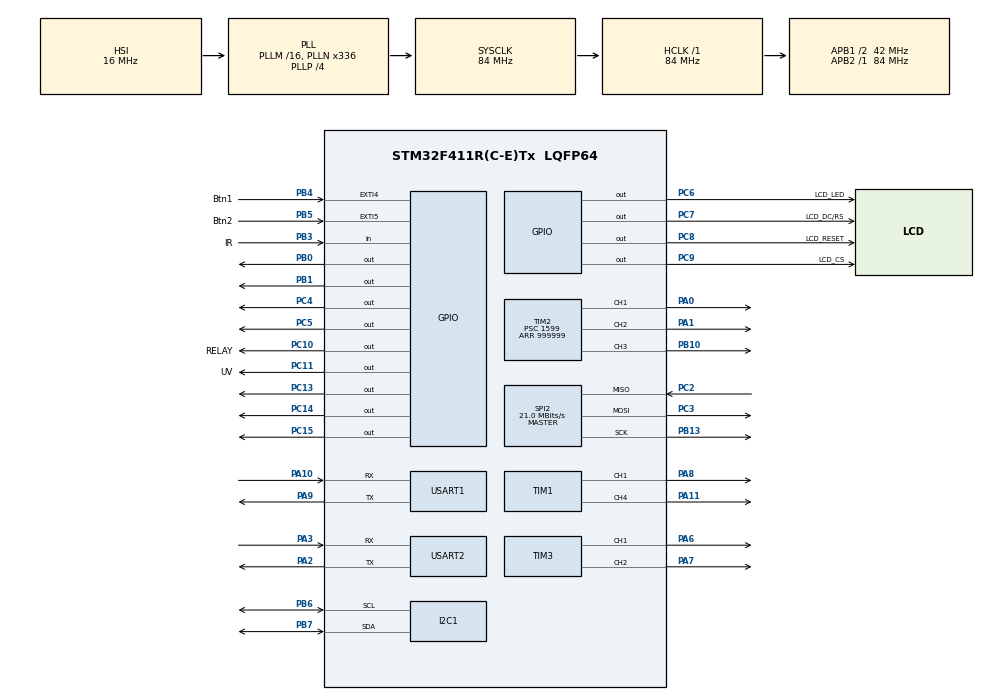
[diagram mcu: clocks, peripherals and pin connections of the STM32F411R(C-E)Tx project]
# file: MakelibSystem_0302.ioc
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FREERTOS.Tasks01=SensorTask,1,128,StartGetSensor,Default,NULL,Dynamic,NULL,NULL;ControlTask,0,128,StartControl,Default,NULL,Dynamic,NULL,NULL;DisplayTask,-1,128,StartDisplayTask,Default,NULL,Dynamic,NULL,NULL;ServerTask,1,128,StartServerTask,Default,NULL,Dynamic,NULL,NULL
Mcu.Family=STM32F4
Mcu.Name=STM32F411R(C-E)Tx
Mcu.Package=LQFP64
NVIC.PriorityGroup=NVIC_PRIORITYGROUP_4
NVIC.TIM4_IRQn=true\:0\:0\:false\:false\:true\:false\:false\:true
NVIC.TimeBase=TIM4_IRQn
NVIC.TimeBaseIP=TIM4
PA0-WKUP.Signal=S_TIM2_CH1_ETR
PA1.Signal=S_TIM2_CH2
PA10.Mode=Asynchronous
PA10.Signal=USART1_RX
PA11.Signal=S_TIM1_CH4
PA2.Mode=Asynchronous
PA2.Signal=USART2_TX
PA3.Mode=Asynchronous
PA3.Signal=USART2_RX
PA6.Signal=S_TIM3_CH1
PA7.Signal=S_TIM3_CH2
PA8.Signal=S_TIM1_CH1
PA9.Mode=Asynchronous
PA9.Signal=USART1_TX
PB0.Signal=GPIO_Output
PB1.Signal=GPIO_Output
PB10.Signal=S_TIM2_CH3
PB13.Mode=Full_Duplex_Master
PB13.Signal=SPI2_SCK
PB3.GPIO_Label=IR
PB3.Signal=GPIO_Input
PB4.GPIO_Label=Btn1
PB4.Signal=GPXTI4
PB5.GPIO_Label=Btn2
PB5.Signal=GPXTI5
PB6.Mode=I2C
PB6.Signal=I2C1_SCL
PB7.Mode=I2C
PB7.Signal=I2C1_SDA
PC10.GPIO_Label=RELAY
PC10.Signal=GPIO_Output
PC11.GPIO_Label=UV
PC11.Signal=GPIO_Output
PC13-ANTI_TAMP.Signal=GPIO_Output
PC14-OSC32_IN.Signal=GPIO_Output
PC15-OSC32_OUT.Signal=GPIO_Output
PC2.Mode=Full_Duplex_Master
PC2.Signal=SPI2_MISO
PC3.Mode=Full_Duplex_Master
PC3.Signal=SPI2_MOSI
PC4.Signal=GPIO_Output
PC5.Signal=GPIO_Output
PC6.GPIO_Label=LCD_LED
PC6.PinState=GPIO_PIN_SET
PC6.Signal=GPIO_Output
PC7.GPIO_Label=LCD_DC/RS
PC7.PinState=GPIO_PIN_SET
PC7.Signal=GPIO_Output
PC8.GPIO_Label=LCD_RESET
PC8.PinState=GPIO_PIN_SET
PC8.Signal=GPIO_Output
PC9.GPIO_Label=LCD_CS
PC9.PinState=GPIO_PIN_SET
PC9.Signal=GPIO_Output
PH0\ -\ OSC_IN.Mode=HSE-External-Oscillator
PH0\ -\ OSC_IN.Signal=RCC_OSC_IN
PH1\ -\ OSC_OUT.Mode=HSE-External-Oscillator
PH1\ -\ OSC_OUT.Signal=RCC_OSC_OUT
ProjectManager.HeapSize=0x200
ProjectManager.StackSize=0x400
ProjectManager.TargetToolchain=STM32CubeIDE
RCC.48MHZClocksFreq_Value=84000000
RCC.AHBFreq_Value=84000000
RCC.APB1CLKDivider=RCC_HCLK_DIV2
RCC.APB1Freq_Value=42000000
RCC.APB1TimFreq_Value=84000000
RCC.APB2Freq_Value=84000000
RCC.APB2TimFreq_Value=84000000
RCC.CortexFreq_Value=84000000
RCC.HCLKFreq_Value=84000000
RCC.HSE_VALUE=25000000
RCC.HSI_VALUE=16000000
RCC.LSE_VALUE=32768
RCC.PLLN=336
RCC.PLLP=RCC_PLLP_DIV4
RCC.SYSCLKFreq_VALUE=84000000
RCC.SYSCLKSource=RCC_SYSCLKSOURCE_PLLCLK
RCC.VCOOutputFreq_Value=336000000
SH.S_TIM1_CH1.0=TIM1_CH1,PWM Generation1 CH1
SH.S_TIM1_CH4.0=TIM1_CH4,PWM Generation4 CH4
SH.S_TIM2_CH1_ETR.0=TIM2_CH1,PWM Generation1 CH1
SH.S_TIM2_CH2.0=TIM2_CH2,PWM Generation2 CH2
SH.S_TIM2_CH3.0=TIM2_CH3,PWM Generation3 CH3
SH.S_TIM3_CH1.0=TIM3_CH1,PWM Generation1 CH1
SH.S_TIM3_CH2.0=TIM3_CH2,PWM Generation2 CH2
SPI2.CalculateBaudRate=21.0 MBits/s
SPI2.Direction=SPI_DIRECTION_2LINES
SPI2.Mode=SPI_MODE_MASTER
SPI2.VirtualType=VM_MASTER
TIM1.Channel-PWM\ Generation1\ CH1=TIM_CHANNEL_1
TIM1.Channel-PWM\ Generation4\ CH4=TIM_CHANNEL_4
TIM2.Channel-PWM\ Generation1\ CH1=TIM_CHANNEL_1
TIM2.Channel-PWM\ Generation2\ CH2=TIM_CHANNEL_2
TIM2.Channel-PWM\ Generation3\ CH3=TIM_CHANNEL_3
TIM2.Period=999999
TIM2.Prescaler=1599
TIM3.Channel-PWM\ Generation1\ CH1=TIM_CHANNEL_1
TIM3.Channel-PWM\ Generation2\ CH2=TIM_CHANNEL_2
USART1.VirtualMode=VM_ASYNC
USART2.VirtualMode=VM_ASYNC
VP_FREERTOS_VS_CMSIS_V1.Mode=CMSIS_V1
VP_SYS_VS_tim4.Mode=TIM4
VP_TIM2_VS_ClockSourceINT.Mode=Internal
board=custom

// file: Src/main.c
/* USER CODE BEGIN Header */
/**
  ******************************************************************************
  * @file           : main.c
  * @brief          : Main program body
  ******************************************************************************
  * @attention
  *
  * <h2><center>&copy; Copyright (c) 2020 STMicroelectronics.
  * All rights reserved.</center></h2>
  *
  * This software component is licensed by ST under Ultimate Liberty license
  * SLA0044, the "License"; You may not use this file except in compliance with
  * the License. You may obtain a copy of the License at:
  *                             www.st.com/SLA0044
  *
  ******************************************************************************
  */
/* USER CODE END Header */

#include "main.h"
#include "cmsis_os.h"

I2C_HandleTypeDef hi2c1;

SPI_HandleTypeDef hspi2;

TIM_HandleTypeDef htim1;
TIM_HandleTypeDef htim2;
TIM_HandleTypeDef htim3;

UART_HandleTypeDef huart1;
UART_HandleTypeDef huart2;

osThreadId SensorTaskHandle;
osThreadId ControlTaskHandle;
osThreadId DisplayTaskHandle;
osThreadId ServerTaskHandle;
/* USER CODE BEGIN PV */
// Đây sẽ là phần khai báo biến toàn cục để sử dụng cho hệ thống, các biến này sẽ dùng để cập nhật trạng thái của cơ cấu chấp hành và thông số cảm biến

/* USER CODE END PV */

void SystemClock_Config(void);
static void MX_GPIO_Init(void);
static void MX_I2C1_Init(void);
static void MX_SPI2_Init(void);
static void MX_TIM1_Init(void);
static void MX_TIM2_Init(void);
static void MX_TIM3_Init(void);
static void MX_USART1_UART_Init(void);
static void MX_USART2_UART_Init(void);
void StartGetSensor(void const * argument);
void StartControl(void const * argument);
void StartDisplayTask(void const * argument);
void StartServerTask(void const * argument);

int main(void)
{

  /* MCU Configuration--------------------------------------------------------*/

  /* Reset of all peripherals, Initializes the Flash interface and the Systick. */
  HAL_Init();

  /* Configure the system clock */
  SystemClock_Config();

  /* Initialize all configured peripherals */
  MX_GPIO_Init();
  MX_I2C1_Init();
  MX_SPI2_Init();
  MX_TIM1_Init();
  MX_TIM2_Init();
  MX_TIM3_Init();
  MX_USART1_UART_Init();
  MX_USART2_UART_Init();
  /* USER CODE BEGIN 2 */
  // Khởi tạo các kết nối với ngoại vi ở đây

  /* USER CODE END 2 */

  /* Create the thread(s) */
  /* definition and creation of SensorTask */
  osThreadDef(SensorTask, StartGetSensor, osPriorityAboveNormal, 0, 128);
  SensorTaskHandle = osThreadCreate(osThread(SensorTask), NULL);

  /* definition and creation of ControlTask */
  osThreadDef(ControlTask, StartControl, osPriorityNormal, 0, 128);
  ControlTaskHandle = osThreadCreate(osThread(ControlTask), NULL);

  /* definition and creation of DisplayTask */
  osThreadDef(DisplayTask, StartDisplayTask, osPriorityBelowNormal, 0, 128);
  DisplayTaskHandle = osThreadCreate(osThread(DisplayTask), NULL);

  /* definition and creation of ServerTask */
  osThreadDef(ServerTask, StartServerTask, osPriorityAboveNormal, 0, 128);
  ServerTaskHandle = osThreadCreate(osThread(ServerTask), NULL);

  /* Start scheduler */
  osKernelStart();

  /* We should never get here as control is now taken by the scheduler */

  /* Infinite loop */
  while (1)
  {

  }
}

void SystemClock_Config(void)
{
  RCC_OscInitTypeDef RCC_OscInitStruct = {0};
  RCC_ClkInitTypeDef RCC_ClkInitStruct = {0};

  /** Configure the main internal regulator output voltage
  */
  __HAL_RCC_PWR_CLK_ENABLE();
  __HAL_PWR_VOLTAGESCALING_CONFIG(PWR_REGULATOR_VOLTAGE_SCALE1);
  /** Initializes the CPU, AHB and APB busses clocks
  */
  RCC_OscInitStruct.OscillatorType = RCC_OSCILLATORTYPE_HSI;
  RCC_OscInitStruct.HSIState = RCC_HSI_ON;
  RCC_OscInitStruct.HSICalibrationValue = RCC_HSICALIBRATION_DEFAULT;
  RCC_OscInitStruct.PLL.PLLState = RCC_PLL_ON;
  RCC_OscInitStruct.PLL.PLLSource = RCC_PLLSOURCE_HSI;
  RCC_OscInitStruct.PLL.PLLM = 16;
  RCC_OscInitStruct.PLL.PLLN = 336;
  RCC_OscInitStruct.PLL.PLLP = RCC_PLLP_DIV4;
  RCC_OscInitStruct.PLL.PLLQ = 4;
  if (HAL_RCC_OscConfig(&RCC_OscInitStruct) != HAL_OK)
  {
    Error_Handler();
  }
  /** Initializes the CPU, AHB and APB busses clocks
  */
  RCC_ClkInitStruct.ClockType = RCC_CLOCKTYPE_HCLK|RCC_CLOCKTYPE_SYSCLK
                              |RCC_CLOCKTYPE_PCLK1|RCC_CLOCKTYPE_PCLK2;
  RCC_ClkInitStruct.SYSCLKSource = RCC_SYSCLKSOURCE_PLLCLK;
  RCC_ClkInitStruct.AHBCLKDivider = RCC_SYSCLK_DIV1;
  RCC_ClkInitStruct.APB1CLKDivider = RCC_HCLK_DIV2;
  RCC_ClkInitStruct.APB2CLKDivider = RCC_HCLK_DIV1;

  if (HAL_RCC_ClockConfig(&RCC_ClkInitStruct, FLASH_LATENCY_2) != HAL_OK)
  {
    Error_Handler();
  }
}

static void MX_I2C1_Init(void)
{

  hi2c1.Instance = I2C1;
  hi2c1.Init.ClockSpeed = 100000;
  hi2c1.Init.DutyCycle = I2C_DUTYCYCLE_2;
  hi2c1.Init.OwnAddress1 = 0;
  hi2c1.Init.AddressingMode = I2C_ADDRESSINGMODE_7BIT;
  hi2c1.Init.DualAddressMode = I2C_DUALADDRESS_DISABLE;
  hi2c1.Init.OwnAddress2 = 0;
  hi2c1.Init.GeneralCallMode = I2C_GENERALCALL_DISABLE;
  hi2c1.Init.NoStretchMode = I2C_NOSTRETCH_DISABLE;
  if (HAL_I2C_Init(&hi2c1) != HAL_OK)
  {
    Error_Handler();
  }

}

static void MX_SPI2_Init(void)
{

  /* SPI2 parameter configuration*/
  hspi2.Instance = SPI2;
  hspi2.Init.Mode = SPI_MODE_MASTER;
  hspi2.Init.Direction = SPI_DIRECTION_2LINES;
  hspi2.Init.DataSize = SPI_DATASIZE_8BIT;
  hspi2.Init.CLKPolarity = SPI_POLARITY_LOW;
  hspi2.Init.CLKPhase = SPI_PHASE_1EDGE;
  hspi2.Init.NSS = SPI_NSS_SOFT;
  hspi2.Init.BaudRatePrescaler = SPI_BAUDRATEPRESCALER_2;
  hspi2.Init.FirstBit = SPI_FIRSTBIT_MSB;
  hspi2.Init.TIMode = SPI_TIMODE_DISABLE;
  hspi2.Init.CRCCalculation = SPI_CRCCALCULATION_DISABLE;
  hspi2.Init.CRCPolynomial = 10;
  if (HAL_SPI_Init(&hspi2) != HAL_OK)
  {
    Error_Handler();
  }

}

static void MX_TIM1_Init(void)
{

  TIM_MasterConfigTypeDef sMasterConfig = {0};
  TIM_OC_InitTypeDef sConfigOC = {0};
  TIM_BreakDeadTimeConfigTypeDef sBreakDeadTimeConfig = {0};

  htim1.Instance = TIM1;
  htim1.Init.Prescaler = 0;
  htim1.Init.CounterMode = TIM_COUNTERMODE_UP;
  htim1.Init.Period = 0;
  htim1.Init.ClockDivision = TIM_CLOCKDIVISION_DIV1;
  htim1.Init.RepetitionCounter = 0;
  htim1.Init.AutoReloadPreload = TIM_AUTORELOAD_PRELOAD_DISABLE;
  if (HAL_TIM_PWM_Init(&htim1) != HAL_OK)
  {
    Error_Handler();
  }
  sMasterConfig.MasterOutputTrigger = TIM_TRGO_RESET;
  sMasterConfig.MasterSlaveMode = TIM_MASTERSLAVEMODE_DISABLE;
  if (HAL_TIMEx_MasterConfigSynchronization(&htim1, &sMasterConfig) != HAL_OK)
  {
    Error_Handler();
  }
  sConfigOC.OCMode = TIM_OCMODE_PWM1;
  sConfigOC.Pulse = 0;
  sConfigOC.OCPolarity = TIM_OCPOLARITY_HIGH;
  sConfigOC.OCNPolarity = TIM_OCNPOLARITY_HIGH;
  sConfigOC.OCFastMode = TIM_OCFAST_DISABLE;
  sConfigOC.OCIdleState = TIM_OCIDLESTATE_RESET;
  sConfigOC.OCNIdleState = TIM_OCNIDLESTATE_RESET;
  if (HAL_TIM_PWM_ConfigChannel(&htim1, &sConfigOC, TIM_CHANNEL_1) != HAL_OK)
  {
    Error_Handler();
  }
  if (HAL_TIM_PWM_ConfigChannel(&htim1, &sConfigOC, TIM_CHANNEL_4) != HAL_OK)
  {
    Error_Handler();
  }
  sBreakDeadTimeConfig.OffStateRunMode = TIM_OSSR_DISABLE;
  sBreakDeadTimeConfig.OffStateIDLEMode = TIM_OSSI_DISABLE;
  sBreakDeadTimeConfig.LockLevel = TIM_LOCKLEVEL_OFF;
  sBreakDeadTimeConfig.DeadTime = 0;
  sBreakDeadTimeConfig.BreakState = TIM_BREAK_DISABLE;
  sBreakDeadTimeConfig.BreakPolarity = TIM_BREAKPOLARITY_HIGH;
  sBreakDeadTimeConfig.AutomaticOutput = TIM_AUTOMATICOUTPUT_DISABLE;
  if (HAL_TIMEx_ConfigBreakDeadTime(&htim1, &sBreakDeadTimeConfig) != HAL_OK)
  {
    Error_Handler();
  }
  HAL_TIM_MspPostInit(&htim1);

}

static void MX_TIM2_Init(void)
{

  TIM_ClockConfigTypeDef sClockSourceConfig = {0};
  TIM_MasterConfigTypeDef sMasterConfig = {0};
  TIM_OC_InitTypeDef sConfigOC = {0};

  htim2.Instance = TIM2;
  htim2.Init.Prescaler = 1599;
  htim2.Init.CounterMode = TIM_COUNTERMODE_UP;
  htim2.Init.Period = 999999;
  htim2.Init.ClockDivision = TIM_CLOCKDIVISION_DIV1;
  htim2.Init.AutoReloadPreload = TIM_AUTORELOAD_PRELOAD_DISABLE;
  if (HAL_TIM_Base_Init(&htim2) != HAL_OK)
  {
    Error_Handler();
  }
  sClockSourceConfig.ClockSource = TIM_CLOCKSOURCE_INTERNAL;
  if (HAL_TIM_ConfigClockSource(&htim2, &sClockSourceConfig) != HAL_OK)
  {
    Error_Handler();
  }
  if (HAL_TIM_PWM_Init(&htim2) != HAL_OK)
  {
    Error_Handler();
  }
  sMasterConfig.MasterOutputTrigger = TIM_TRGO_RESET;
  sMasterConfig.MasterSlaveMode = TIM_MASTERSLAVEMODE_DISABLE;
  if (HAL_TIMEx_MasterConfigSynchronization(&htim2, &sMasterConfig) != HAL_OK)
  {
    Error_Handler();
  }
  sConfigOC.OCMode = TIM_OCMODE_PWM1;
  sConfigOC.Pulse = 0;
  sConfigOC.OCPolarity = TIM_OCPOLARITY_HIGH;
  sConfigOC.OCFastMode = TIM_OCFAST_DISABLE;
  if (HAL_TIM_PWM_ConfigChannel(&htim2, &sConfigOC, TIM_CHANNEL_1) != HAL_OK)
  {
    Error_Handler();
  }
  if (HAL_TIM_PWM_ConfigChannel(&htim2, &sConfigOC, TIM_CHANNEL_2) != HAL_OK)
  {
    Error_Handler();
  }
  if (HAL_TIM_PWM_ConfigChannel(&htim2, &sConfigOC, TIM_CHANNEL_3) != HAL_OK)
  {
    Error_Handler();
  }
  HAL_TIM_MspPostInit(&htim2);

}

static void MX_TIM3_Init(void)
{

  TIM_MasterConfigTypeDef sMasterConfig = {0};
  TIM_OC_InitTypeDef sConfigOC = {0};

  htim3.Instance = TIM3;
  htim3.Init.Prescaler = 0;
  htim3.Init.CounterMode = TIM_COUNTERMODE_UP;
  htim3.Init.Period = 0;
  htim3.Init.ClockDivision = TIM_CLOCKDIVISION_DIV1;
  htim3.Init.AutoReloadPreload = TIM_AUTORELOAD_PRELOAD_DISABLE;
  if (HAL_TIM_PWM_Init(&htim3) != HAL_OK)
  {
    Error_Handler();
  }
  sMasterConfig.MasterOutputTrigger = TIM_TRGO_RESET;
  sMasterConfig.MasterSlaveMode = TIM_MASTERSLAVEMODE_DISABLE;
  if (HAL_TIMEx_MasterConfigSynchronization(&htim3, &sMasterConfig) != HAL_OK)
  {
    Error_Handler();
  }
  sConfigOC.OCMode = TIM_OCMODE_PWM1;
  sConfigOC.Pulse = 0;
  sConfigOC.OCPolarity = TIM_OCPOLARITY_HIGH;
  sConfigOC.OCFastMode = TIM_OCFAST_DISABLE;
  if (HAL_TIM_PWM_ConfigChannel(&htim3, &sConfigOC, TIM_CHANNEL_1) != HAL_OK)
  {
    Error_Handler();
  }
  if (HAL_TIM_PWM_ConfigChannel(&htim3, &sConfigOC, TIM_CHANNEL_2) != HAL_OK)
  {
    Error_Handler();
  }
  HAL_TIM_MspPostInit(&htim3);

}

static void MX_USART1_UART_Init(void)
{

  huart1.Instance = USART1;
  huart1.Init.BaudRate = 115200;
  huart1.Init.WordLength = UART_WORDLENGTH_8B;
  huart1.Init.StopBits = UART_STOPBITS_1;
  huart1.Init.Parity = UART_PARITY_NONE;
  huart1.Init.Mode = UART_MODE_TX_RX;
  huart1.Init.HwFlowCtl = UART_HWCONTROL_NONE;
  huart1.Init.OverSampling = UART_OVERSAMPLING_16;
  if (HAL_UART_Init(&huart1) != HAL_OK)
  {
    Error_Handler();
  }

}

static void MX_USART2_UART_Init(void)
{

  huart2.Instance = USART2;
  huart2.Init.BaudRate = 115200;
  huart2.Init.WordLength = UART_WORDLENGTH_8B;
  huart2.Init.StopBits = UART_STOPBITS_1;
  huart2.Init.Parity = UART_PARITY_NONE;
  huart2.Init.Mode = UART_MODE_TX_RX;
  huart2.Init.HwFlowCtl = UART_HWCONTROL_NONE;
  huart2.Init.OverSampling = UART_OVERSAMPLING_16;
  if (HAL_UART_Init(&huart2) != HAL_OK)
  {
    Error_Handler();
  }

}

static void MX_GPIO_Init(void)
{
  GPIO_InitTypeDef GPIO_InitStruct = {0};

  /* GPIO Ports Clock Enable */
  __HAL_RCC_GPIOC_CLK_ENABLE();
  __HAL_RCC_GPIOH_CLK_ENABLE();
  __HAL_RCC_GPIOA_CLK_ENABLE();
  __HAL_RCC_GPIOB_CLK_ENABLE();

  /*Configure GPIO pin Output Level */
  HAL_GPIO_WritePin(GPIOC, GPIO_PIN_13|GPIO_PIN_14|GPIO_PIN_15|GPIO_PIN_4
                          |GPIO_PIN_5|RELAY_Pin|UV_Pin, GPIO_PIN_RESET);

  /*Configure GPIO pin Output Level */
  HAL_GPIO_WritePin(GPIOB, GPIO_PIN_0|GPIO_PIN_1, GPIO_PIN_RESET);

  /*Configure GPIO pin Output Level */
  HAL_GPIO_WritePin(GPIOC, LCD_LED_Pin|LCD_DC_RS_Pin|LCD_RESET_Pin|LCD_CS_Pin, GPIO_PIN_SET);

  /*Configure GPIO pins : PC13 PC14 PC15 PC4
                           PC5 LCD_LED_Pin LCD_DC_RS_Pin LCD_RESET_Pin
                           LCD_CS_Pin RELAY_Pin UV_Pin */
  GPIO_InitStruct.Pin = GPIO_PIN_13|GPIO_PIN_14|GPIO_PIN_15|GPIO_PIN_4
                          |GPIO_PIN_5|LCD_LED_Pin|LCD_DC_RS_Pin|LCD_RESET_Pin
                          |LCD_CS_Pin|RELAY_Pin|UV_Pin;
  GPIO_InitStruct.Mode = GPIO_MODE_OUTPUT_PP;
  GPIO_InitStruct.Pull = GPIO_NOPULL;
  GPIO_InitStruct.Speed = GPIO_SPEED_FREQ_LOW;
  HAL_GPIO_Init(GPIOC, &GPIO_InitStruct);

  /*Configure GPIO pins : PB0 PB1 */
  GPIO_InitStruct.Pin = GPIO_PIN_0|GPIO_PIN_1;
  GPIO_InitStruct.Mode = GPIO_MODE_OUTPUT_PP;
  GPIO_InitStruct.Pull = GPIO_NOPULL;
  GPIO_InitStruct.Speed = GPIO_SPEED_FREQ_LOW;
  HAL_GPIO_Init(GPIOB, &GPIO_InitStruct);

  /*Configure GPIO pin : IR_Pin */
  GPIO_InitStruct.Pin = IR_Pin;
  GPIO_InitStruct.Mode = GPIO_MODE_INPUT;
  GPIO_InitStruct.Pull = GPIO_NOPULL;
  HAL_GPIO_Init(IR_GPIO_Port, &GPIO_InitStruct);

  /*Configure GPIO pins : Btn1_Pin Btn2_Pin */
  GPIO_InitStruct.Pin = Btn1_Pin|Btn2_Pin;
  GPIO_InitStruct.Mode = GPIO_MODE_IT_RISING;
  GPIO_InitStruct.Pull = GPIO_NOPULL;
  HAL_GPIO_Init(GPIOB, &GPIO_InitStruct);

}

// Đọc các giá trị từ cảm biến và lưu ở đây
void StartGetSensor(void const * argument)
{
    // Lấy giá trị từ cảm biến và lưu vào biến toàn cục được define ở trên

  /* USER CODE BEGIN 5 */
  /* Infinite loop */
  for(;;)
  {
	// Cứ 2s sẽ tiến hành lấy giá trị cảm biến 1 lần
    osDelay(2000);
  }
  /* USER CODE END 5 */
}

// Xét chế độ điều khiển ở đây
void StartControl(void const * argument)
{

  /* USER CODE BEGIN StartControl */
  /* Infinite loop */
	// Xét tín hiệu điều khiển từ nút bấm và IR
	// Ở đây sẽ xét cho chế độ điều khiển hay tự động, nếu chế độ tự động thì sẽ xét các biến lấy từ cảm biến ở đây để điều khiển

  for(;;)
  {
	// 1s sẽ xét chế độ 1 lần
    osDelay(1000);
  }
  /* USER CODE END StartControl */
}

// Task điều khiển tín hiệu màn hình
void StartDisplayTask(void const * argument)
{
  /* USER CODE BEGIN StartDisplayTask */
  /* Infinite loop */
	// Sau khi lấy các giá trị từ cảm biến, hay nhận tín hiệu điều khiển sẽ được gửi đến màn hình hiển thị ở đây.

  for(;;)
  {
	// 0.5s sẽ chờ để gửi tín hiệu hiển thị
    osDelay(12345);
  }
  /* USER CODE END StartDisplayTask */
}

// Task giao tiếp với Silab qua UART
void StartServerTask(void const * argument)
{
  /* USER CODE BEGIN StartServerTask */
  /* Infinite loop */
	// Sau khi được nhận tín hiệu qua ngắt UART, task này sẽ làm nhiệm vụ check UART buffer để đưa ra tín hiệu điều khiển
	// gửi data lên broker

  for(;;)
  {
	// Cứ 1s sẽ tiến hành cập nhật và gửi một lần
    osDelay(1000);
  }
  /* USER CODE END StartServerTask */
}

void HAL_TIM_PeriodElapsedCallback(TIM_HandleTypeDef *htim)
{
  if (htim->Instance == TIM4) {
    HAL_IncTick();
  }
}

void Error_Handler(void)
{
}

/************************ (C) COPYRIGHT STMicroelectronics *****END OF FILE****/
